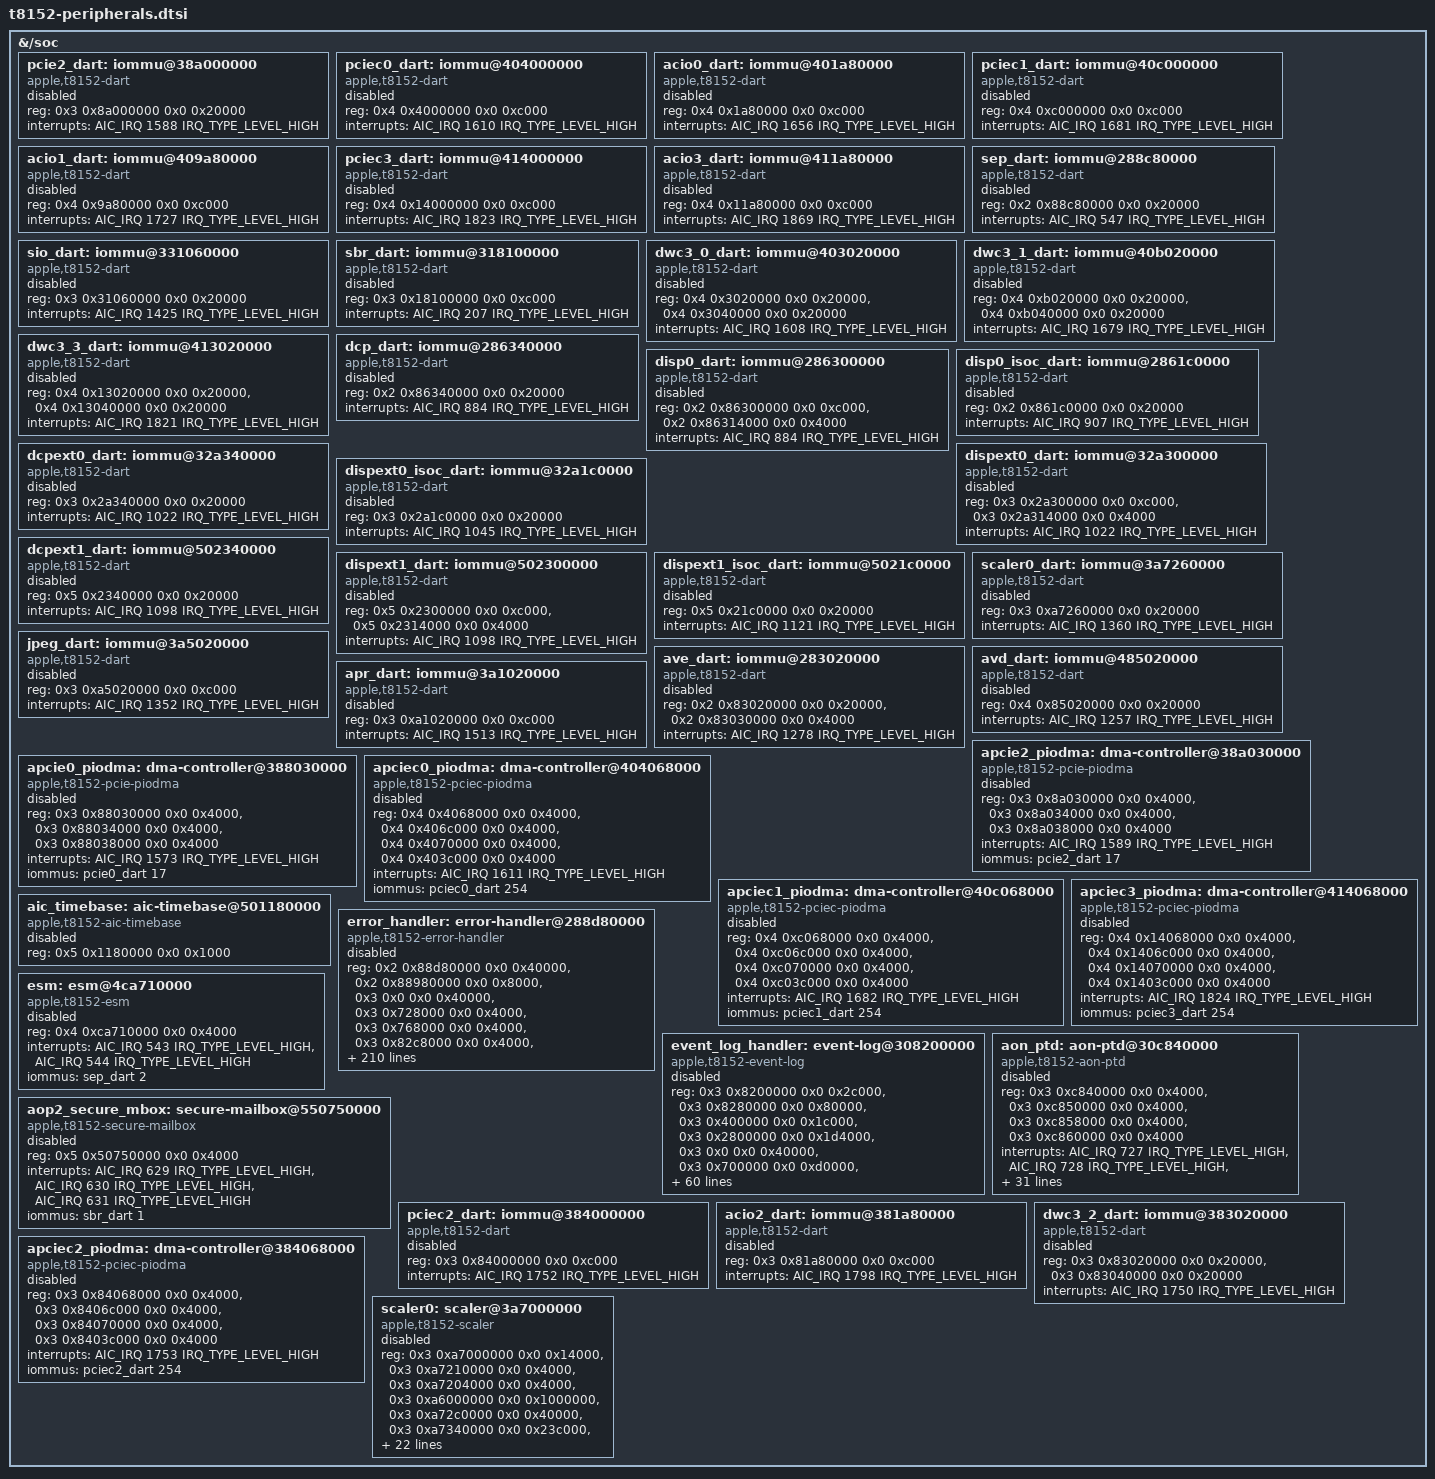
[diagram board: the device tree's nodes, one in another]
// SPDX-License-Identifier: GPL-2.0+ OR MIT
/* Shared SoC resources; firmware ownership and enables need qualification. */

&{/soc} {
	pcie2_dart: iommu@38a000000 {
		compatible = "apple,t8152-dart", "apple,t8110-dart";
		reg = <0x3 0x8a000000 0x0 0x20000>;
		interrupts = <AIC_IRQ 1588 IRQ_TYPE_LEVEL_HIGH>;
		#iommu-cells = <1>;
		status = "disabled";
	};

	pciec0_dart: iommu@404000000 {
		compatible = "apple,t8152-dart", "apple,t8110-dart";
		reg = <0x4 0x4000000 0x0 0xc000>;
		interrupts = <AIC_IRQ 1610 IRQ_TYPE_LEVEL_HIGH>;
		#iommu-cells = <1>;
		status = "disabled";
	};

	acio0_dart: iommu@401a80000 {
		compatible = "apple,t8152-dart", "apple,t8110-dart";
		reg = <0x4 0x1a80000 0x0 0xc000>;
		interrupts = <AIC_IRQ 1656 IRQ_TYPE_LEVEL_HIGH>;
		#iommu-cells = <1>;
		status = "disabled";
	};

	pciec1_dart: iommu@40c000000 {
		compatible = "apple,t8152-dart", "apple,t8110-dart";
		reg = <0x4 0xc000000 0x0 0xc000>;
		interrupts = <AIC_IRQ 1681 IRQ_TYPE_LEVEL_HIGH>;
		#iommu-cells = <1>;
		status = "disabled";
	};

	acio1_dart: iommu@409a80000 {
		compatible = "apple,t8152-dart", "apple,t8110-dart";
		reg = <0x4 0x9a80000 0x0 0xc000>;
		interrupts = <AIC_IRQ 1727 IRQ_TYPE_LEVEL_HIGH>;
		#iommu-cells = <1>;
		status = "disabled";
	};

	pciec3_dart: iommu@414000000 {
		compatible = "apple,t8152-dart", "apple,t8110-dart";
		reg = <0x4 0x14000000 0x0 0xc000>;
		interrupts = <AIC_IRQ 1823 IRQ_TYPE_LEVEL_HIGH>;
		#iommu-cells = <1>;
		status = "disabled";
	};

	acio3_dart: iommu@411a80000 {
		compatible = "apple,t8152-dart", "apple,t8110-dart";
		reg = <0x4 0x11a80000 0x0 0xc000>;
		interrupts = <AIC_IRQ 1869 IRQ_TYPE_LEVEL_HIGH>;
		#iommu-cells = <1>;
		status = "disabled";
	};

	sep_dart: iommu@288c80000 {
		compatible = "apple,t8152-dart", "apple,t8110-dart";
		reg = <0x2 0x88c80000 0x0 0x20000>;
		interrupts = <AIC_IRQ 547 IRQ_TYPE_LEVEL_HIGH>;
		#iommu-cells = <1>;
		status = "disabled";
	};

	sio_dart: iommu@331060000 {
		compatible = "apple,t8152-dart", "apple,t8110-dart";
		reg = <0x3 0x31060000 0x0 0x20000>;
		interrupts = <AIC_IRQ 1425 IRQ_TYPE_LEVEL_HIGH>;
		#iommu-cells = <1>;
		status = "disabled";
	};

	sbr_dart: iommu@318100000 {
		compatible = "apple,t8152-dart", "apple,t8110-dart";
		reg = <0x3 0x18100000 0x0 0xc000>;
		interrupts = <AIC_IRQ 207 IRQ_TYPE_LEVEL_HIGH>;
		#iommu-cells = <1>;
		status = "disabled";
	};

	dwc3_0_dart: iommu@403020000 {
		compatible = "apple,t8152-dart", "apple,t8110-dart";
		reg = <0x4 0x3020000 0x0 0x20000>,
		      <0x4 0x3040000 0x0 0x20000>;
		interrupts = <AIC_IRQ 1608 IRQ_TYPE_LEVEL_HIGH>;
		#iommu-cells = <1>;
		status = "disabled";
	};

	dwc3_1_dart: iommu@40b020000 {
		compatible = "apple,t8152-dart", "apple,t8110-dart";
		reg = <0x4 0xb020000 0x0 0x20000>,
		      <0x4 0xb040000 0x0 0x20000>;
		interrupts = <AIC_IRQ 1679 IRQ_TYPE_LEVEL_HIGH>;
		#iommu-cells = <1>;
		status = "disabled";
	};

	dwc3_3_dart: iommu@413020000 {
		compatible = "apple,t8152-dart", "apple,t8110-dart";
		reg = <0x4 0x13020000 0x0 0x20000>,
		      <0x4 0x13040000 0x0 0x20000>;
		interrupts = <AIC_IRQ 1821 IRQ_TYPE_LEVEL_HIGH>;
		#iommu-cells = <1>;
		status = "disabled";
	};

	dcp_dart: iommu@286340000 {
		compatible = "apple,t8152-dart", "apple,t8110-dart";
		reg = <0x2 0x86340000 0x0 0x20000>;
		interrupts = <AIC_IRQ 884 IRQ_TYPE_LEVEL_HIGH>;
		#iommu-cells = <1>;
		status = "disabled";
	};

	disp0_dart: iommu@286300000 {
		compatible = "apple,t8152-dart", "apple,t8110-dart";
		reg = <0x2 0x86300000 0x0 0xc000>,
		      <0x2 0x86314000 0x0 0x4000>;
		interrupts = <AIC_IRQ 884 IRQ_TYPE_LEVEL_HIGH>;
		#iommu-cells = <1>;
		status = "disabled";
	};

	disp0_isoc_dart: iommu@2861c0000 {
		compatible = "apple,t8152-dart", "apple,t8110-dart";
		reg = <0x2 0x861c0000 0x0 0x20000>;
		interrupts = <AIC_IRQ 907 IRQ_TYPE_LEVEL_HIGH>;
		#iommu-cells = <1>;
		status = "disabled";
	};

	dcpext0_dart: iommu@32a340000 {
		compatible = "apple,t8152-dart", "apple,t8110-dart";
		reg = <0x3 0x2a340000 0x0 0x20000>;
		interrupts = <AIC_IRQ 1022 IRQ_TYPE_LEVEL_HIGH>;
		#iommu-cells = <1>;
		status = "disabled";
	};

	dispext0_dart: iommu@32a300000 {
		compatible = "apple,t8152-dart", "apple,t8110-dart";
		reg = <0x3 0x2a300000 0x0 0xc000>,
		      <0x3 0x2a314000 0x0 0x4000>;
		interrupts = <AIC_IRQ 1022 IRQ_TYPE_LEVEL_HIGH>;
		#iommu-cells = <1>;
		status = "disabled";
	};

	dispext0_isoc_dart: iommu@32a1c0000 {
		compatible = "apple,t8152-dart", "apple,t8110-dart";
		reg = <0x3 0x2a1c0000 0x0 0x20000>;
		interrupts = <AIC_IRQ 1045 IRQ_TYPE_LEVEL_HIGH>;
		#iommu-cells = <1>;
		status = "disabled";
	};

	dcpext1_dart: iommu@502340000 {
		compatible = "apple,t8152-dart", "apple,t8110-dart";
		reg = <0x5 0x2340000 0x0 0x20000>;
		interrupts = <AIC_IRQ 1098 IRQ_TYPE_LEVEL_HIGH>;
		#iommu-cells = <1>;
		status = "disabled";
	};

	dispext1_dart: iommu@502300000 {
		compatible = "apple,t8152-dart", "apple,t8110-dart";
		reg = <0x5 0x2300000 0x0 0xc000>,
		      <0x5 0x2314000 0x0 0x4000>;
		interrupts = <AIC_IRQ 1098 IRQ_TYPE_LEVEL_HIGH>;
		#iommu-cells = <1>;
		status = "disabled";
	};

	dispext1_isoc_dart: iommu@5021c0000 {
		compatible = "apple,t8152-dart", "apple,t8110-dart";
		reg = <0x5 0x21c0000 0x0 0x20000>;
		interrupts = <AIC_IRQ 1121 IRQ_TYPE_LEVEL_HIGH>;
		#iommu-cells = <1>;
		status = "disabled";
	};

	scaler0_dart: iommu@3a7260000 {
		compatible = "apple,t8152-dart", "apple,t8110-dart";
		reg = <0x3 0xa7260000 0x0 0x20000>;
		interrupts = <AIC_IRQ 1360 IRQ_TYPE_LEVEL_HIGH>;
		#iommu-cells = <1>;
		/* A dedicated scaler-DART gate mapping is not published by this ADT. */
		status = "disabled";
	};

	jpeg_dart: iommu@3a5020000 {
		compatible = "apple,t8152-dart", "apple,t8110-dart";
		reg = <0x3 0xa5020000 0x0 0xc000>;
		interrupts = <AIC_IRQ 1352 IRQ_TYPE_LEVEL_HIGH>;
		#iommu-cells = <1>;
		status = "disabled";
	};

	ave_dart: iommu@283020000 {
		compatible = "apple,t8152-dart", "apple,t8110-dart";
		reg = <0x2 0x83020000 0x0 0x20000>,
		      <0x2 0x83030000 0x0 0x4000>;
		interrupts = <AIC_IRQ 1278 IRQ_TYPE_LEVEL_HIGH>;
		#iommu-cells = <1>;
		status = "disabled";
	};

	avd_dart: iommu@485020000 {
		compatible = "apple,t8152-dart", "apple,t8110-dart";
		reg = <0x4 0x85020000 0x0 0x20000>;
		interrupts = <AIC_IRQ 1257 IRQ_TYPE_LEVEL_HIGH>;
		#iommu-cells = <1>;
		status = "disabled";
	};

	apr_dart: iommu@3a1020000 {
		compatible = "apple,t8152-dart", "apple,t8110-dart";
		reg = <0x3 0xa1020000 0x0 0xc000>;
		interrupts = <AIC_IRQ 1513 IRQ_TYPE_LEVEL_HIGH>;
		#iommu-cells = <1>;
		status = "disabled";
	};

	apcie2_piodma: dma-controller@38a030000 {
		compatible = "apple,t8152-pcie-piodma", "apple,pcie-piodma";
		reg = <0x3 0x8a030000 0x0 0x4000>,
		      <0x3 0x8a034000 0x0 0x4000>,
		      <0x3 0x8a038000 0x0 0x4000>;
		interrupts = <AIC_IRQ 1589 IRQ_TYPE_LEVEL_HIGH>;
		iommus = <&pcie2_dart 17>;
		status = "disabled";
	};

	apcie0_piodma: dma-controller@388030000 {
		compatible = "apple,t8152-pcie-piodma", "apple,pcie-piodma";
		reg = <0x3 0x88030000 0x0 0x4000>,
		      <0x3 0x88034000 0x0 0x4000>,
		      <0x3 0x88038000 0x0 0x4000>;
		interrupts = <AIC_IRQ 1573 IRQ_TYPE_LEVEL_HIGH>;
		iommus = <&pcie0_dart 17>;
		status = "disabled";
	};

	apciec0_piodma: dma-controller@404068000 {
		compatible = "apple,t8152-pciec-piodma", "apple,pciec-piodma";
		reg = <0x4 0x4068000 0x0 0x4000>,
		      <0x4 0x406c000 0x0 0x4000>,
		      <0x4 0x4070000 0x0 0x4000>,
		      <0x4 0x403c000 0x0 0x4000>;
		interrupts = <AIC_IRQ 1611 IRQ_TYPE_LEVEL_HIGH>;
		iommus = <&pciec0_dart 254>;
		status = "disabled";
	};

	apciec1_piodma: dma-controller@40c068000 {
		compatible = "apple,t8152-pciec-piodma", "apple,pciec-piodma";
		reg = <0x4 0xc068000 0x0 0x4000>,
		      <0x4 0xc06c000 0x0 0x4000>,
		      <0x4 0xc070000 0x0 0x4000>,
		      <0x4 0xc03c000 0x0 0x4000>;
		interrupts = <AIC_IRQ 1682 IRQ_TYPE_LEVEL_HIGH>;
		iommus = <&pciec1_dart 254>;
		status = "disabled";
	};

	apciec3_piodma: dma-controller@414068000 {
		compatible = "apple,t8152-pciec-piodma", "apple,pciec-piodma";
		reg = <0x4 0x14068000 0x0 0x4000>,
		      <0x4 0x1406c000 0x0 0x4000>,
		      <0x4 0x14070000 0x0 0x4000>,
		      <0x4 0x1403c000 0x0 0x4000>;
		interrupts = <AIC_IRQ 1824 IRQ_TYPE_LEVEL_HIGH>;
		iommus = <&pciec3_dart 254>;
		status = "disabled";
	};

	aic_timebase: aic-timebase@501180000 {
		compatible = "apple,t8152-aic-timebase", "apple,aic-timebase";
		reg = <0x5 0x1180000 0x0 0x1000>;
		status = "disabled";
	};

	error_handler: error-handler@288d80000 {
		compatible = "apple,t8152-error-handler", "apple,soc-error-handler";
		reg = <0x2 0x88d80000 0x0 0x40000>,
		      <0x2 0x88980000 0x0 0x8000>,
		      <0x3 0x0 0x0 0x40000>,
		      <0x3 0x728000 0x0 0x4000>,
		      <0x3 0x768000 0x0 0x4000>,
		      <0x3 0x82c8000 0x0 0x4000>,
		      <0x3 0x2000000 0x0 0x1000000>,
		      <0x3 0x700000 0x0 0x1c000>,
		      <0x2 0x20000000 0x0 0x140000>,
		      <0x2 0x21000000 0x0 0x40000>,
		      <0x2 0x21200000 0x0 0x40000>,
		      <0x2 0x21400000 0x0 0x40000>,
		      <0x2 0x21600000 0x0 0x40000>,
		      <0x2 0x21800000 0x0 0x40000>,
		      <0x2 0x21a00000 0x0 0x40000>,
		      <0x2 0x21c00000 0x0 0x40000>,
		      <0x2 0x21e00000 0x0 0x40000>,
		      <0x2 0x4f000000 0x0 0x8000>,
		      <0x2 0x50000000 0x0 0x8000>,
		      <0x2 0x51000000 0x0 0x8000>,
		      <0x2 0x52000000 0x0 0x8000>,
		      <0x2 0x53000000 0x0 0x8000>,
		      <0x2 0x54000000 0x0 0x8000>,
		      <0x2 0x55000000 0x0 0x8000>,
		      <0x2 0x56000000 0x0 0x8000>,
		      <0x2 0x5f000000 0x0 0x1000000>,
		      <0x2 0x6f000000 0x0 0x1000000>,
		      <0x2 0x57000000 0x0 0x1000000>,
		      <0x2 0x58000000 0x0 0x1000000>,
		      <0x3 0x770000 0x0 0x4000>,
		      <0x3 0x771000 0x0 0x4000>,
		      <0x2 0x5b000000 0x0 0x24000>,
		      <0x3 0x3520000 0x0 0x4000>,
		      <0x3 0x3080000 0x0 0x18000>,
		      <0x3 0x3700000 0x0 0x8000>,
		      <0x3 0x3100000 0x0 0x20000>,
		      <0x3 0x440000 0x0 0x4000>,
		      <0x3 0x444000 0x0 0x4000>,
		      <0x3 0x18008000 0x0 0x4000>,
		      <0x3 0x1800c000 0x0 0x4000>,
		      <0x3 0x2fb48000 0x0 0x4000>,
		      <0x3 0x2fb4c000 0x0 0x4000>,
		      <0x4 0x19a08000 0x0 0x4000>,
		      <0x4 0x19a0c000 0x0 0x4000>,
		      <0x4 0x81a08000 0x0 0x4000>,
		      <0x4 0x81a0c000 0x0 0x4000>,
		      <0x2 0x86288000 0x0 0x4000>,
		      <0x2 0x8628c000 0x0 0x4000>,
		      <0x3 0x2a288000 0x0 0x4000>,
		      <0x3 0x2a28c000 0x0 0x4000>,
		      <0x5 0x2288000 0x0 0x4000>,
		      <0x5 0x228c000 0x0 0x4000>,
		      <0x4 0x85088000 0x0 0x4000>,
		      <0x4 0x8508c000 0x0 0x4000>,
		      <0x2 0x83088000 0x0 0x4000>,
		      <0x2 0x8308c000 0x0 0x4000>,
		      <0x5 0x80f48000 0x0 0x4000>,
		      <0x5 0x80f4c000 0x0 0x4000>,
		      <0x3 0x22008000 0x0 0x4000>,
		      <0x3 0x2200c000 0x0 0x4000>,
		      <0x3 0xa5108000 0x0 0x4000>,
		      <0x3 0xa510c000 0x0 0x4000>,
		      <0x3 0xa75c8000 0x0 0x4000>,
		      <0x3 0xa75cc000 0x0 0x4000>,
		      <0x3 0x31088000 0x0 0x4000>,
		      <0x3 0x3108c000 0x0 0x4000>,
		      <0x3 0xa1388000 0x0 0x4000>,
		      <0x3 0xa138c000 0x0 0x4000>,
		      <0x3 0x8d048000 0x0 0x4000>,
		      <0x3 0x8d04c000 0x0 0x4000>,
		      <0x4 0x5008000 0x0 0x4000>,
		      <0x4 0x500c000 0x0 0x4000>,
		      <0x4 0xd008000 0x0 0x4000>,
		      <0x4 0xd00c000 0x0 0x4000>,
		      <0x3 0x85008000 0x0 0x4000>,
		      <0x3 0x8500c000 0x0 0x4000>,
		      <0x4 0x15008000 0x0 0x4000>,
		      <0x4 0x1500c000 0x0 0x4000>,
		      <0x3 0x16000000 0x0 0x1c000>,
		      <0x3 0x2d700000 0x0 0xf4000>,
		      <0x3 0x2e7c8000 0x0 0x14000>,
		      <0x3 0x2e5c8000 0x0 0x14000>,
		      <0x3 0x10700000 0x0 0x14000>,
		      <0x3 0x11700000 0x0 0x14000>,
		      <0x3 0xc700000 0x0 0x14000>,
		      <0x4 0x19700000 0x0 0x14000>,
		      <0x4 0x81700000 0x0 0x14000>,
		      <0x2 0x86f00000 0x0 0x14000>,
		      <0x3 0x2af00000 0x0 0x14000>,
		      <0x5 0x2f00000 0x0 0x14000>,
		      <0x3 0xf00000 0x0 0x14000>,
		      <0x3 0x3148000 0x0 0x14000>,
		      <0x3 0x3a00000 0x0 0x1c000>,
		      <0x4 0x85548000 0x0 0x14000>,
		      <0x2 0x81700000 0x0 0x14000>,
		      <0x5 0x82700000 0x0 0x14000>,
		      <0x5 0x82f00000 0x0 0x14000>,
		      <0x3 0x21700000 0x0 0x14000>,
		      <0x3 0xa7488000 0x0 0x14000>,
		      <0x3 0x31f00000 0x0 0x14000>,
		      <0x3 0x14700000 0x0 0x14000>,
		      <0x4 0x18000000 0x0 0x8000>,
		      <0x4 0x80000000 0x0 0x8000>,
		      <0x2 0x87000000 0x0 0x8000>,
		      <0x3 0x2b000000 0x0 0x8000>,
		      <0x5 0x3000000 0x0 0x8000>,
		      <0x2 0x80000000 0x0 0x8000>,
		      <0x5 0x81000000 0x0 0x8000>,
		      <0x3 0x23000000 0x0 0x8000>,
		      <0x4 0x0 0x0 0x8000>,
		      <0x4 0x8000000 0x0 0x8000>,
		      <0x3 0x80000000 0x0 0x8000>,
		      <0x4 0x10000000 0x0 0x8000>,
		      <0x4 0x84000000 0x0 0x8000>,
		      <0x3 0x2c000000 0x0 0x8000>,
		      <0x3 0xa4000000 0x0 0x8000>,
		      <0x3 0x8e000000 0x0 0x8000>,
		      <0x3 0x30000000 0x0 0x8000>,
		      <0x3 0x19000000 0x0 0x8000>,
		      <0x3 0xa0000000 0x0 0x8000>;
		interrupts = <AIC_IRQ 546 IRQ_TYPE_LEVEL_HIGH>,
		             <AIC_IRQ 550 IRQ_TYPE_LEVEL_HIGH>,
		             <AIC_IRQ 545 IRQ_TYPE_LEVEL_HIGH>,
		             <AIC_IRQ 1226 IRQ_TYPE_LEVEL_HIGH>,
		             <AIC_IRQ 1220 IRQ_TYPE_LEVEL_HIGH>,
		             <AIC_IRQ 457 IRQ_TYPE_LEVEL_HIGH>,
		             <AIC_IRQ 459 IRQ_TYPE_LEVEL_HIGH>,
		             <AIC_IRQ 461 IRQ_TYPE_LEVEL_HIGH>,
		             <AIC_IRQ 463 IRQ_TYPE_LEVEL_HIGH>,
		             <AIC_IRQ 465 IRQ_TYPE_LEVEL_HIGH>,
		             <AIC_IRQ 468 IRQ_TYPE_LEVEL_HIGH>,
		             <AIC_IRQ 471 IRQ_TYPE_LEVEL_HIGH>,
		             <AIC_IRQ 474 IRQ_TYPE_LEVEL_HIGH>,
		             <AIC_IRQ 477 IRQ_TYPE_LEVEL_HIGH>,
		             <AIC_IRQ 480 IRQ_TYPE_LEVEL_HIGH>,
		             <AIC_IRQ 483 IRQ_TYPE_LEVEL_HIGH>,
		             <AIC_IRQ 486 IRQ_TYPE_LEVEL_HIGH>,
		             <AIC_IRQ 126 IRQ_TYPE_LEVEL_HIGH>,
		             <AIC_IRQ 127 IRQ_TYPE_LEVEL_HIGH>,
		             <AIC_IRQ 128 IRQ_TYPE_LEVEL_HIGH>,
		             <AIC_IRQ 129 IRQ_TYPE_LEVEL_HIGH>,
		             <AIC_IRQ 130 IRQ_TYPE_LEVEL_HIGH>,
		             <AIC_IRQ 131 IRQ_TYPE_LEVEL_HIGH>,
		             <AIC_IRQ 132 IRQ_TYPE_LEVEL_HIGH>,
		             <AIC_IRQ 133 IRQ_TYPE_LEVEL_HIGH>,
		             <AIC_IRQ 139 IRQ_TYPE_LEVEL_HIGH>,
		             <AIC_IRQ 138 IRQ_TYPE_LEVEL_HIGH>,
		             <AIC_IRQ 134 IRQ_TYPE_LEVEL_HIGH>,
		             <AIC_IRQ 135 IRQ_TYPE_LEVEL_HIGH>,
		             <AIC_IRQ 409 IRQ_TYPE_LEVEL_HIGH>,
		             <AIC_IRQ 136 IRQ_TYPE_LEVEL_HIGH>,
		             <AIC_IRQ 1234 IRQ_TYPE_LEVEL_HIGH>,
		             <AIC_IRQ 1202 IRQ_TYPE_LEVEL_HIGH>,
		             <AIC_IRQ 1204 IRQ_TYPE_LEVEL_HIGH>,
		             <AIC_IRQ 210 IRQ_TYPE_LEVEL_HIGH>,
		             <AIC_IRQ 536 IRQ_TYPE_LEVEL_HIGH>,
		             <AIC_IRQ 787 IRQ_TYPE_LEVEL_HIGH>,
		             <AIC_IRQ 835 IRQ_TYPE_LEVEL_HIGH>,
		             <AIC_IRQ 912 IRQ_TYPE_LEVEL_HIGH>,
		             <AIC_IRQ 1050 IRQ_TYPE_LEVEL_HIGH>,
		             <AIC_IRQ 1126 IRQ_TYPE_LEVEL_HIGH>,
		             <AIC_IRQ 1266 IRQ_TYPE_LEVEL_HIGH>,
		             <AIC_IRQ 1293 IRQ_TYPE_LEVEL_HIGH>,
		             <AIC_IRQ 1315 IRQ_TYPE_LEVEL_HIGH>,
		             <AIC_IRQ 1343 IRQ_TYPE_LEVEL_HIGH>,
		             <AIC_IRQ 1355 IRQ_TYPE_LEVEL_HIGH>,
		             <AIC_IRQ 1365 IRQ_TYPE_LEVEL_HIGH>,
		             <AIC_IRQ 1430 IRQ_TYPE_LEVEL_HIGH>,
		             <AIC_IRQ 1559 IRQ_TYPE_LEVEL_HIGH>,
		             <AIC_IRQ 1565 IRQ_TYPE_LEVEL_HIGH>,
		             <AIC_IRQ 1606 IRQ_TYPE_LEVEL_HIGH>,
		             <AIC_IRQ 1677 IRQ_TYPE_LEVEL_HIGH>,
		             <AIC_IRQ 1748 IRQ_TYPE_LEVEL_HIGH>,
		             <AIC_IRQ 1819 IRQ_TYPE_LEVEL_HIGH>,
		             <AIC_IRQ 214 IRQ_TYPE_LEVEL_HIGH>,
		             <AIC_IRQ 510 IRQ_TYPE_LEVEL_HIGH>,
		             <AIC_IRQ 519 IRQ_TYPE_LEVEL_HIGH>,
		             <AIC_IRQ 525 IRQ_TYPE_LEVEL_HIGH>,
		             <AIC_IRQ 625 IRQ_TYPE_LEVEL_HIGH>,
		             <AIC_IRQ 632 IRQ_TYPE_LEVEL_HIGH>,
		             <AIC_IRQ 763 IRQ_TYPE_LEVEL_HIGH>,
		             <AIC_IRQ 784 IRQ_TYPE_LEVEL_HIGH>,
		             <AIC_IRQ 832 IRQ_TYPE_LEVEL_HIGH>,
		             <AIC_IRQ 871 IRQ_TYPE_LEVEL_HIGH>,
		             <AIC_IRQ 1009 IRQ_TYPE_LEVEL_HIGH>,
		             <AIC_IRQ 1085 IRQ_TYPE_LEVEL_HIGH>,
		             <AIC_IRQ 1159 IRQ_TYPE_LEVEL_HIGH>,
		             <AIC_IRQ 1237 IRQ_TYPE_LEVEL_HIGH>,
		             <AIC_IRQ 1245 IRQ_TYPE_LEVEL_HIGH>,
		             <AIC_IRQ 1254 IRQ_TYPE_LEVEL_HIGH>,
		             <AIC_IRQ 1276 IRQ_TYPE_LEVEL_HIGH>,
		             <AIC_IRQ 1318 IRQ_TYPE_LEVEL_HIGH>,
		             <AIC_IRQ 1324 IRQ_TYPE_LEVEL_HIGH>,
		             <AIC_IRQ 1345 IRQ_TYPE_LEVEL_HIGH>,
		             <AIC_IRQ 1378 IRQ_TYPE_LEVEL_HIGH>,
		             <AIC_IRQ 1395 IRQ_TYPE_LEVEL_HIGH>,
		             <AIC_IRQ 1499 IRQ_TYPE_LEVEL_HIGH>,
		             <AIC_IRQ 790 IRQ_TYPE_LEVEL_HIGH>,
		             <AIC_IRQ 838 IRQ_TYPE_LEVEL_HIGH>,
		             <AIC_IRQ 888 IRQ_TYPE_LEVEL_HIGH>,
		             <AIC_IRQ 1026 IRQ_TYPE_LEVEL_HIGH>,
		             <AIC_IRQ 1102 IRQ_TYPE_LEVEL_HIGH>,
		             <AIC_IRQ 1281 IRQ_TYPE_LEVEL_HIGH>,
		             <AIC_IRQ 1302 IRQ_TYPE_LEVEL_HIGH>,
		             <AIC_IRQ 1340 IRQ_TYPE_LEVEL_HIGH>,
		             <AIC_IRQ 1598 IRQ_TYPE_LEVEL_HIGH>,
		             <AIC_IRQ 1669 IRQ_TYPE_LEVEL_HIGH>,
		             <AIC_IRQ 1740 IRQ_TYPE_LEVEL_HIGH>,
		             <AIC_IRQ 1811 IRQ_TYPE_LEVEL_HIGH>,
		             <AIC_IRQ 1261 IRQ_TYPE_LEVEL_HIGH>,
		             <AIC_IRQ 535 IRQ_TYPE_LEVEL_HIGH>,
		             <AIC_IRQ 1353 IRQ_TYPE_LEVEL_HIGH>,
		             <AIC_IRQ 1561 IRQ_TYPE_LEVEL_HIGH>,
		             <AIC_IRQ 1427 IRQ_TYPE_LEVEL_HIGH>,
		             <AIC_IRQ 212 IRQ_TYPE_LEVEL_HIGH>,
		             <AIC_IRQ 1512 IRQ_TYPE_LEVEL_HIGH>;
		/* Shared status windows do not grant AP ownership. */
		status = "disabled";
	};

	event_log_handler: event-log@308200000 {
		compatible = "apple,t8152-event-log", "apple,soc-event-log";
		reg = <0x3 0x8200000 0x0 0x2c000>,
		      <0x3 0x8280000 0x0 0x80000>,
		      <0x3 0x400000 0x0 0x1c000>,
		      <0x3 0x2800000 0x0 0x1d4000>,
		      <0x3 0x0 0x0 0x40000>,
		      <0x3 0x700000 0x0 0xd0000>,
		      <0x3 0x75e000 0x0 0x1000>,
		      <0x3 0x270000 0x0 0x4000>,
		      <0x3 0x274000 0x0 0x4000>,
		      <0x3 0x210000 0x0 0x4000>,
		      <0x3 0x214e00 0x0 0x4000>,
		      <0x3 0x214800 0x0 0x4000>,
		      <0x3 0x214f00 0x0 0x80>,
		      <0x3 0x217e00 0x0 0x4000>,
		      <0x3 0x213e00 0x0 0x4000>,
		      <0x3 0x213800 0x0 0x4000>,
		      <0x3 0x213f00 0x0 0x80>,
		      <0x3 0x217a00 0x0 0x4000>,
		      <0x3 0x215600 0x0 0x4000>,
		      <0x3 0x215000 0x0 0x4000>,
		      <0x3 0x215700 0x0 0x80>,
		      <0x3 0x218000 0x0 0x4000>,
		      <0x3 0x216e00 0x0 0x4000>,
		      <0x3 0x216800 0x0 0x4000>,
		      <0x3 0x216f00 0x0 0x80>,
		      <0x3 0x218400 0x0 0x4000>,
		      <0x3 0x217600 0x0 0x4000>,
		      <0x3 0x217000 0x0 0x4000>,
		      <0x3 0x217700 0x0 0x80>,
		      <0x3 0x218600 0x0 0x4000>,
		      <0x3 0x216600 0x0 0x4000>,
		      <0x3 0x216000 0x0 0x4000>,
		      <0x3 0x216700 0x0 0x80>,
		      <0x3 0x218200 0x0 0x4000>,
		      <0x3 0x215e00 0x0 0x4000>,
		      <0x3 0x215800 0x0 0x4000>,
		      <0x3 0x215f00 0x0 0x80>,
		      <0x3 0x212e00 0x0 0x4000>,
		      <0x3 0x212800 0x0 0x4000>,
		      <0x3 0x212f00 0x0 0x80>,
		      <0x3 0x217800 0x0 0x4000>,
		      <0x3 0x213600 0x0 0x4000>,
		      <0x3 0x213000 0x0 0x4000>,
		      <0x3 0x213700 0x0 0x80>,
		      <0x3 0x214600 0x0 0x4000>,
		      <0x3 0x214000 0x0 0x4000>,
		      <0x3 0x214700 0x0 0x80>,
		      <0x3 0x217c00 0x0 0x4000>,
		      <0x3 0x210800 0x0 0x4000>,
		      <0x3 0x210c00 0x0 0x400>,
		      <0x3 0x211000 0x0 0x400>,
		      <0x3 0x211400 0x0 0x400>,
		      <0x3 0x211800 0x0 0x400>,
		      <0x3 0x211c00 0x0 0x400>,
		      <0x3 0x212000 0x0 0x400>,
		      <0x3 0x212400 0x0 0x400>,
		      <0x3 0x3dc000 0x0 0x4000>;
		interrupts = <AIC_IRQ 25 IRQ_TYPE_LEVEL_HIGH>,
		             <AIC_IRQ 26 IRQ_TYPE_LEVEL_HIGH>,
		             <AIC_IRQ 64 IRQ_TYPE_LEVEL_HIGH>,
		             <AIC_IRQ 403 IRQ_TYPE_LEVEL_HIGH>,
		             <AIC_IRQ 431 IRQ_TYPE_LEVEL_HIGH>,
		             <AIC_IRQ 444 IRQ_TYPE_LEVEL_HIGH>,
		             <AIC_IRQ 453 IRQ_TYPE_LEVEL_HIGH>,
		             <AIC_IRQ 1212 IRQ_TYPE_LEVEL_HIGH>,
		             <AIC_IRQ 1233 IRQ_TYPE_LEVEL_HIGH>;
		/* Shared status windows do not grant AP ownership. */
		status = "disabled";
	};

	esm: esm@4ca710000 {
		compatible = "apple,t8152-esm", "apple,esm";
		reg = <0x4 0xca710000 0x0 0x4000>;
		interrupts = <AIC_IRQ 543 IRQ_TYPE_LEVEL_HIGH>,
		             <AIC_IRQ 544 IRQ_TYPE_LEVEL_HIGH>;
		iommus = <&sep_dart 2>;
		status = "disabled";
	};

	aon_ptd: aon-ptd@30c840000 {
		compatible = "apple,t8152-aon-ptd", "apple,aon-ptd";
		reg = <0x3 0xc840000 0x0 0x4000>,
		      <0x3 0xc850000 0x0 0x4000>,
		      <0x3 0xc858000 0x0 0x4000>,
		      <0x3 0xc860000 0x0 0x4000>;
		interrupts = <AIC_IRQ 727 IRQ_TYPE_LEVEL_HIGH>,
		             <AIC_IRQ 728 IRQ_TYPE_LEVEL_HIGH>,
		             <AIC_IRQ 729 IRQ_TYPE_LEVEL_HIGH>,
		             <AIC_IRQ 730 IRQ_TYPE_LEVEL_HIGH>,
		             <AIC_IRQ 731 IRQ_TYPE_LEVEL_HIGH>,
		             <AIC_IRQ 732 IRQ_TYPE_LEVEL_HIGH>,
		             <AIC_IRQ 733 IRQ_TYPE_LEVEL_HIGH>,
		             <AIC_IRQ 734 IRQ_TYPE_LEVEL_HIGH>,
		             <AIC_IRQ 735 IRQ_TYPE_LEVEL_HIGH>,
		             <AIC_IRQ 736 IRQ_TYPE_LEVEL_HIGH>,
		             <AIC_IRQ 737 IRQ_TYPE_LEVEL_HIGH>,
		             <AIC_IRQ 738 IRQ_TYPE_LEVEL_HIGH>,
		             <AIC_IRQ 739 IRQ_TYPE_LEVEL_HIGH>,
		             <AIC_IRQ 740 IRQ_TYPE_LEVEL_HIGH>,
		             <AIC_IRQ 741 IRQ_TYPE_LEVEL_HIGH>,
		             <AIC_IRQ 742 IRQ_TYPE_LEVEL_HIGH>,
		             <AIC_IRQ 743 IRQ_TYPE_LEVEL_HIGH>,
		             <AIC_IRQ 744 IRQ_TYPE_LEVEL_HIGH>,
		             <AIC_IRQ 745 IRQ_TYPE_LEVEL_HIGH>,
		             <AIC_IRQ 746 IRQ_TYPE_LEVEL_HIGH>,
		             <AIC_IRQ 747 IRQ_TYPE_LEVEL_HIGH>,
		             <AIC_IRQ 748 IRQ_TYPE_LEVEL_HIGH>,
		             <AIC_IRQ 749 IRQ_TYPE_LEVEL_HIGH>,
		             <AIC_IRQ 750 IRQ_TYPE_LEVEL_HIGH>,
		             <AIC_IRQ 751 IRQ_TYPE_LEVEL_HIGH>,
		             <AIC_IRQ 752 IRQ_TYPE_LEVEL_HIGH>,
		             <AIC_IRQ 753 IRQ_TYPE_LEVEL_HIGH>,
		             <AIC_IRQ 754 IRQ_TYPE_LEVEL_HIGH>,
		             <AIC_IRQ 755 IRQ_TYPE_LEVEL_HIGH>,
		             <AIC_IRQ 756 IRQ_TYPE_LEVEL_HIGH>,
		             <AIC_IRQ 757 IRQ_TYPE_LEVEL_HIGH>,
		             <AIC_IRQ 758 IRQ_TYPE_LEVEL_HIGH>;
		interrupt-controller;
		#interrupt-cells = <1>;
		#address-cells = <0>;
		status = "disabled";
	};

	aop2_secure_mbox: secure-mailbox@550750000 {
		compatible = "apple,t8152-secure-mailbox", "apple,secure-mailbox";
		reg = <0x5 0x50750000 0x0 0x4000>;
		interrupts = <AIC_IRQ 629 IRQ_TYPE_LEVEL_HIGH>,
		             <AIC_IRQ 630 IRQ_TYPE_LEVEL_HIGH>,
		             <AIC_IRQ 631 IRQ_TYPE_LEVEL_HIGH>;
		iommus = <&sbr_dart 1>;
		status = "disabled";
	};

	pciec2_dart: iommu@384000000 {
		compatible = "apple,t8152-dart", "apple,t8110-dart";
		reg = <0x3 0x84000000 0x0 0xc000>;
		interrupts = <AIC_IRQ 1752 IRQ_TYPE_LEVEL_HIGH>;
		#iommu-cells = <1>;
		status = "disabled";
	};

	acio2_dart: iommu@381a80000 {
		compatible = "apple,t8152-dart", "apple,t8110-dart";
		reg = <0x3 0x81a80000 0x0 0xc000>;
		interrupts = <AIC_IRQ 1798 IRQ_TYPE_LEVEL_HIGH>;
		#iommu-cells = <1>;
		status = "disabled";
	};

	dwc3_2_dart: iommu@383020000 {
		compatible = "apple,t8152-dart", "apple,t8110-dart";
		reg = <0x3 0x83020000 0x0 0x20000>,
		      <0x3 0x83040000 0x0 0x20000>;
		interrupts = <AIC_IRQ 1750 IRQ_TYPE_LEVEL_HIGH>;
		#iommu-cells = <1>;
		status = "disabled";
	};

	apciec2_piodma: dma-controller@384068000 {
		compatible = "apple,t8152-pciec-piodma", "apple,pciec-piodma";
		reg = <0x3 0x84068000 0x0 0x4000>,
		      <0x3 0x8406c000 0x0 0x4000>,
		      <0x3 0x84070000 0x0 0x4000>,
		      <0x3 0x8403c000 0x0 0x4000>;
		interrupts = <AIC_IRQ 1753 IRQ_TYPE_LEVEL_HIGH>;
		iommus = <&pciec2_dart 254>;
		status = "disabled";
	};
};

&{/soc} {
	scaler0: scaler@3a7000000 {
		compatible = "apple,t8152-scaler", "apple,scaler-v23";
		reg = <0x3 0xa7000000 0x0 0x14000>,
		      <0x3 0xa7210000 0x0 0x4000>,
		      <0x3 0xa7204000 0x0 0x4000>,
		      <0x3 0xa6000000 0x0 0x1000000>,
		      <0x3 0xa72c0000 0x0 0x40000>,
		      <0x3 0xa7340000 0x0 0x23c000>,
		      <0x3 0xa72a0000 0x0 0x4000>,
		      <0x3 0xa7208000 0x0 0x4000>,
		      <0x3 0x700000 0x0 0xd0000>,
		      <0x3 0xa7210000 0x0 0x4000>,
		      <0x3 0xa7220000 0x0 0x4000>,
		      <0x3 0x16020000 0x0 0x10000>;
		interrupts = <AIC_IRQ 1359 IRQ_TYPE_LEVEL_HIGH>,
		             <AIC_IRQ 1361 IRQ_TYPE_LEVEL_HIGH>,
		             <AIC_IRQ 1362 IRQ_TYPE_LEVEL_HIGH>,
		             <AIC_IRQ 1363 IRQ_TYPE_LEVEL_HIGH>,
		             <AIC_IRQ 1367 IRQ_TYPE_LEVEL_HIGH>,
		             <AIC_IRQ 1368 IRQ_TYPE_LEVEL_HIGH>,
		             <AIC_IRQ 1369 IRQ_TYPE_LEVEL_HIGH>,
		             <AIC_IRQ 1370 IRQ_TYPE_LEVEL_HIGH>,
		             <AIC_IRQ 1371 IRQ_TYPE_LEVEL_HIGH>,
		             <AIC_IRQ 1372 IRQ_TYPE_LEVEL_HIGH>,
		             <AIC_IRQ 1373 IRQ_TYPE_LEVEL_HIGH>,
		             <AIC_IRQ 1374 IRQ_TYPE_LEVEL_HIGH>,
		             <AIC_IRQ 269 IRQ_TYPE_LEVEL_HIGH>,
		             <AIC_IRQ 309 IRQ_TYPE_LEVEL_HIGH>,
		             <AIC_IRQ 229 IRQ_TYPE_LEVEL_HIGH>;
		iommus = <&scaler0_dart 0>, <&scaler0_dart 1>;
		/* PMGR2 clock, power and reset providers need qualification. */
		status = "disabled";
	};
};
